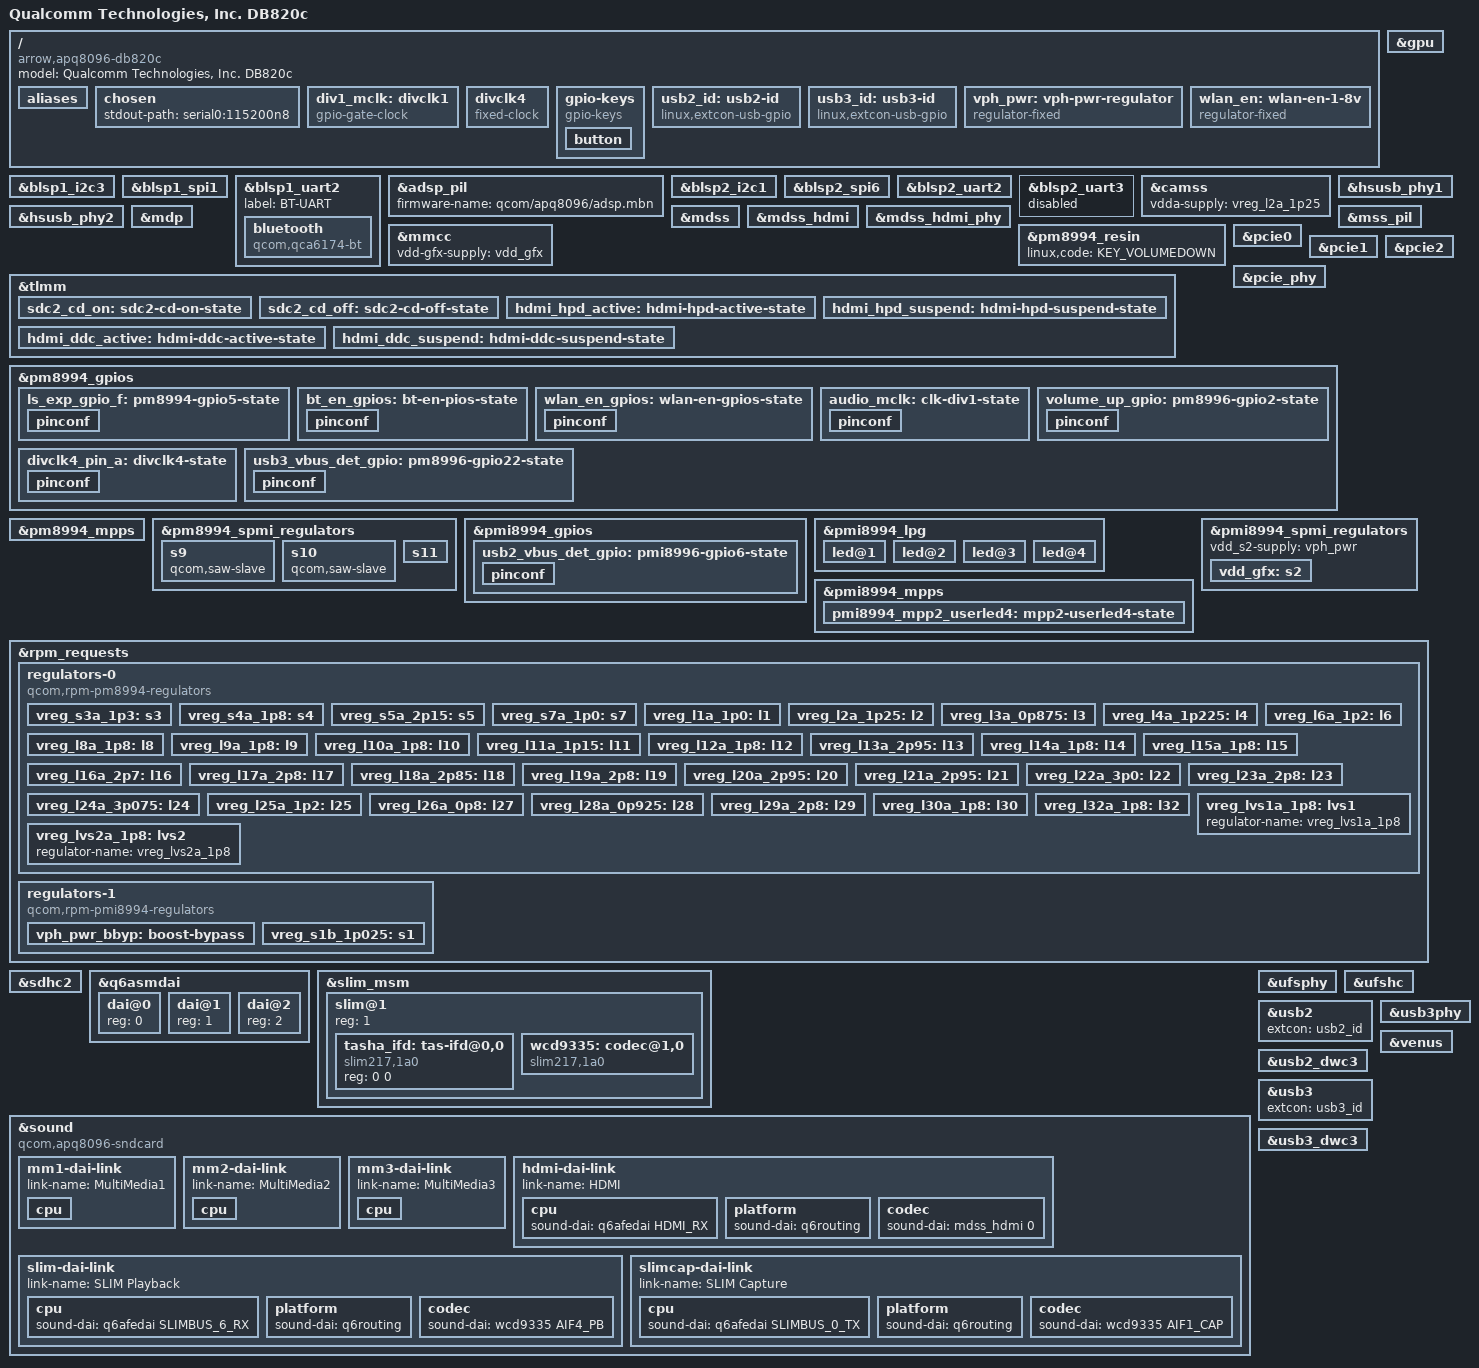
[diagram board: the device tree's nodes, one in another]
/dts-v1/;
#include "msm8996.dtsi"
#include "pm8994.dtsi"
#include "pmi8994.dtsi"
#include <dt-bindings/input/input.h>
#include <dt-bindings/gpio/gpio.h>
#include <dt-bindings/leds/common.h>
#include <dt-bindings/pinctrl/qcom,pmic-gpio.h>
#include <dt-bindings/sound/qcom,q6afe.h>
#include <dt-bindings/sound/qcom,q6asm.h>
#include <dt-bindings/sound/qcom,wcd9335.h>
/ {
	model = "Qualcomm Technologies, Inc. DB820c";
	compatible = "arrow,apq8096-db820c", "qcom,apq8096-sbc", "qcom,apq8096";
	aliases {
		serial0 = &blsp2_uart2;
		serial1 = &blsp2_uart3;
		serial2 = &blsp1_uart2;
		i2c0 = &blsp1_i2c3;
		i2c1 = &blsp2_i2c1;
		i2c2 = &blsp2_i2c1;
		spi0 = &blsp1_spi1;
		spi1 = &blsp2_spi6;
	};
	chosen {
		stdout-path = "serial0:115200n8";
	};
	div1_mclk: divclk1 {
		compatible = "gpio-gate-clock";
		pinctrl-0 = <&audio_mclk>;
		pinctrl-names = "default";
		clocks = <&rpmcc RPM_SMD_DIV_CLK1>;
		#clock-cells = <0>;
		enable-gpios = <&pm8994_gpios 15 0>;
	};
	divclk4: divclk4 {
		compatible = "fixed-clock";
		#clock-cells = <0>;
		clock-frequency = <32768>;
		clock-output-names = "divclk4";
		pinctrl-names = "default";
		pinctrl-0 = <&divclk4_pin_a>;
	};
	gpio-keys {
		compatible = "gpio-keys";
		autorepeat;
		pinctrl-names = "default";
		pinctrl-0 = <&volume_up_gpio>;
		button {
			label = "Volume Up";
			linux,code = <KEY_VOLUMEUP>;
			gpios = <&pm8994_gpios 2 GPIO_ACTIVE_LOW>;
		};
	};
	usb2_id: usb2-id {
		compatible = "linux,extcon-usb-gpio";
		id-gpios = <&pmi8994_gpios 6 GPIO_ACTIVE_HIGH>;
		pinctrl-names = "default";
		pinctrl-0 = <&usb2_vbus_det_gpio>;
	};
	usb3_id: usb3-id {
		compatible = "linux,extcon-usb-gpio";
		id-gpios = <&pm8994_gpios 22 GPIO_ACTIVE_HIGH>;
		pinctrl-names = "default";
		pinctrl-0 = <&usb3_vbus_det_gpio>;
	};
	vph_pwr: vph-pwr-regulator {
		compatible = "regulator-fixed";
		regulator-name = "vph_pwr";
		regulator-always-on;
		regulator-boot-on;
		regulator-min-microvolt = <3700000>;
		regulator-max-microvolt = <3700000>;
	};
	wlan_en: wlan-en-1-8v {
		pinctrl-names = "default";
		pinctrl-0 = <&wlan_en_gpios>;
		compatible = "regulator-fixed";
		regulator-name = "wlan-en-regulator";
		regulator-min-microvolt = <1800000>;
		regulator-max-microvolt = <1800000>;
		gpio = <&pm8994_gpios 8 0>;
		startup-delay-us = <70000>;
		enable-active-high;
	};
};
&blsp1_i2c3 {
	status = "okay";
};
&blsp1_spi1 {
	status = "okay";
};
&blsp1_uart2 {
	label = "BT-UART";
	status = "okay";
	bluetooth {
		compatible = "qcom,qca6174-bt";
		enable-gpios = <&pm8994_gpios 19 GPIO_ACTIVE_HIGH>;
		clocks = <&divclk4>;
	};
};
&adsp_pil {
	status = "okay";
	firmware-name = "qcom/apq8096/adsp.mbn";
};
&blsp2_i2c1 {
	status = "okay";
};
&blsp2_i2c1 {
	status = "okay";
};
&blsp2_spi6 {
	status = "okay";
};
&blsp2_uart2 {
	label = "LS-UART1";
	status = "okay";
	pinctrl-names = "default", "sleep";
	pinctrl-0 = <&blsp2_uart2_2pins_default>;
	pinctrl-1 = <&blsp2_uart2_2pins_sleep>;
};
&blsp2_uart3 {
	label = "LS-UART0";
	status = "disabled";
	pinctrl-names = "default", "sleep";
	pinctrl-0 = <&blsp2_uart3_4pins_default>;
	pinctrl-1 = <&blsp2_uart3_4pins_sleep>;
};
&camss {
	vdda-supply = <&vreg_l2a_1p25>;
};
&gpu {
	status = "okay";
};
&hsusb_phy1 {
	status = "okay";
	vdd-supply = <&vreg_l28a_0p925>;
	vdda-pll-supply = <&vreg_l12a_1p8>;
	vdda-phy-dpdm-supply = <&vreg_l24a_3p075>;
};
&hsusb_phy2 {
	status = "okay";
	vdd-supply = <&vreg_l28a_0p925>;
	vdda-pll-supply = <&vreg_l12a_1p8>;
	vdda-phy-dpdm-supply = <&vreg_l24a_3p075>;
};
&mdp {
	status = "okay";
};
&mdss {
	status = "okay";
};
&mdss_hdmi {
	status = "okay";
	pinctrl-names = "default", "sleep";
	pinctrl-0 = <&hdmi_hpd_active &hdmi_ddc_active>;
	pinctrl-1 = <&hdmi_hpd_suspend &hdmi_ddc_suspend>;
	core-vdda-supply = <&vreg_l12a_1p8>;
	core-vcc-supply = <&vreg_s4a_1p8>;
};
&mdss_hdmi_phy {
	status = "okay";
	vddio-supply = <&vreg_l12a_1p8>;
	vcca-supply = <&vreg_l28a_0p925>;
	#phy-cells = <0>;
};
&mmcc {
	vdd-gfx-supply = <&vdd_gfx>;
};
&mss_pil {
	status = "okay";
	pll-supply = <&vreg_l12a_1p8>;
	firmware-name = "qcom/apq8096/mba.mbn", "qcom/apq8096/modem.mbn";
};
&pm8994_resin {
	status = "okay";
	linux,code = <KEY_VOLUMEDOWN>;
};
&tlmm {
	gpio-line-names =
		"[SPI0_DOUT]",  
		"[SPI0_DIN]",  
		"[SPI0_CS]",  
		"[SPI0_SCLK]",  
		"[UART1_TxD]",  
		"[UART1_RxD]",  
		"[I2C1_SDA]",  
		"[I2C1_SCL]",  
		"GPIO-H",  
		"TP93",  
		"GPIO-G",  
		"[MDP_VSYNC_S]",  
		"NC",  
		"[CSI0_MCLK]",  
		"[CAM_MCLK1]",  
		"[CSI1_MCLK]",  
		"TP99",  
		"[I2C2_SDA]",  
		"[I2C2_SCL]",  
		"[CCI_I2C_SDA1]",  
		"[CCI_I2C_SCL1]",  
		"FLASH_STROBE_EN",  
		"FLASH_STROBE_TRIG",  
		"GPIO-K",  
		"GPIO-D",  
		"GPIO-I",  
		"GPIO-J",  
		"BLSP6_I2C_SDA",  
		"BLSP6_I2C_SCL",  
		"GPIO-B",  
		"GPIO30",  
		"HDMI_CEC",  
		"HDMI_DDC_CLOCK",  
		"HDMI_DDC_DATA",  
		"HDMI_HOT_PLUG_DETECT",  
		"PCIE0_RST_N",  
		"PCIE0_CLKREQ_N",  
		"PCIE0_WAKE",  
		"SD_CARD_DET_N",  
		"TSIF1_SYNC",  
		"W_DISABLE_N",  
		"[BLSP9_UART_TX]",  
		"[BLSP9_UART_RX]",  
		"[BLSP2_UART_CTS_N]",  
		"[BLSP2_UART_RFR_N]",  
		"[BLSP3_UART_TX]",  
		"[BLSP3_UART_RX]",  
		"[I2C0_SDA]",  
		"[I2C0_SCL]",  
		"[UART0_TxD]",  
		"[UART0_RxD]",  
		"[UART0_CTS]",  
		"[UART0_RTS]",  
		"[CODEC_INT1_N]",  
		"[CODEC_INT2_N]",  
		"[BLSP7_I2C_SDA]",  
		"[BLSP7_I2C_SCL]",  
		"MI2S_MCLK",  
		"[PCM_CLK]",  
		"[PCM_FS]",  
		"[PCM_DO]",  
		"[PCM_DI]",  
		"GPIO-E",  
		"TP87",  
		"[CODEC_RST_N]",  
		"[PCM1_CLK]",  
		"[PCM1_SYNC]",  
		"[PCM1_DIN]",  
		"[PCM1_DOUT]",  
		"AUDIO_REF_CLK",  
		"SLIMBUS_CLK",  
		"SLIMBUS_DATA0",  
		"SLIMBUS_DATA1",  
		"NC",  
		"NC",  
		"NC",  
		"NC",  
		"TP94",  
		"NC",  
		"TP95",  
		"GPIO-A",  
		"TP88",  
		"TP89",  
		"TP90",  
		"TP91",  
		"[SD_DAT0]",  
		"[SD_CMD]",  
		"[SD_DAT3]",  
		"[SD_SCLK]",  
		"TSIF1_CLK",  
		"TSIF1_EN",  
		"TSIF1_DATA",  
		"NC",  
		"TSIF2_CLK",  
		"TSIF2_EN",  
		"TSIF2_DATA",  
		"TSIF2_SYNC",  
		"NC",  
		"CAM1_STANDBY_N",  
		"NC",  
		"NC",  
		"[LCD1_RESET_N]",  
		"BOOT_CONFIG1",  
		"USB_HUB_RESET",  
		"CAM1_RST_N",  
		"NC",  
		"NC",  
		"NC",  
		"NC",  
		"NC",  
		"NC",  
		"NC",  
		"NC",  
		"PMI8994_BUA",  
		"PCIE2_RST_N",  
		"PCIE2_CLKREQ_N",  
		"PCIE2_WAKE",  
		"SSC_IRQ_0",  
		"SSC_IRQ_1",  
		"SSC_IRQ_2",  
		"NC",  
		"GPIO121",  
		"NC",  
		"SSC_IRQ_6",  
		"SSC_IRQ_7",  
		"GPIO-C",  
		"BOOT_CONFIG5",  
		"NC",  
		"NC",  
		"BOOT_CONFIG7",  
		"PCIE1_RST_N",  
		"PCIE1_CLKREQ_N",  
		"PCIE1_WAKE",  
		"GPIO-L",  
		"NC",  
		"NC",  
		"BOOT_CONFIG8",  
		"NC",  
		"NC",  
		"GPS_SSBI2",  
		"GPS_SSBI1",  
		"NC",  
		"NC",  
		"NC",  
		"BOOT_CONFIG6",  
		"NC",  
		"NC",  
		"NC",  
		"NC",  
		"NC";  
	sdc2_cd_on: sdc2-cd-on-state {
		pins = "gpio38";
		function = "gpio";
		bias-pull-up;
		drive-strength = <16>;
	};
	sdc2_cd_off: sdc2-cd-off-state {
		pins = "gpio38";
		function = "gpio";
		bias-pull-up;
		drive-strength = <2>;
	};
	hdmi_hpd_active: hdmi-hpd-active-state {
		pins = "gpio34";
		function = "hdmi_hot";
		bias-pull-down;
		drive-strength = <16>;
	};
	hdmi_hpd_suspend: hdmi-hpd-suspend-state {
		pins = "gpio34";
		function = "hdmi_hot";
		bias-pull-down;
		drive-strength = <2>;
	};
	hdmi_ddc_active: hdmi-ddc-active-state {
		pins = "gpio32", "gpio33";
		function = "hdmi_ddc";
		drive-strength = <2>;
		bias-pull-up;
	};
	hdmi_ddc_suspend: hdmi-ddc-suspend-state {
		pins = "gpio32", "gpio33";
		function = "hdmi_ddc";
		drive-strength = <2>;
		bias-pull-down;
	};
};
&pcie0 {
	status = "okay";
	perst-gpios = <&tlmm 35 GPIO_ACTIVE_LOW>;
	vddpe-3v3-supply = <&wlan_en>;
	vdda-supply = <&vreg_l28a_0p925>;
};
&pcie1 {
	status = "okay";
	perst-gpios = <&tlmm 130 GPIO_ACTIVE_LOW>;
	vdda-supply = <&vreg_l28a_0p925>;
};
&pcie2 {
	status = "okay";
	perst-gpios = <&tlmm 114 GPIO_ACTIVE_LOW>;
	vdda-supply = <&vreg_l28a_0p925>;
};
&pcie_phy {
	status = "okay";
	vdda-phy-supply = <&vreg_l28a_0p925>;
	vdda-pll-supply = <&vreg_l12a_1p8>;
};
&pm8994_gpios {
	gpio-line-names =
		"NC",
		"KEY_VOLP_N",
		"NC",
		"BL1_PWM",
		"GPIO-F",  
		"BL1_EN",
		"NC",
		"WLAN_EN",
		"NC",
		"NC",
		"NC",
		"NC",
		"NC",
		"NC",
		"DIVCLK1",
		"DIVCLK2",
		"DIVCLK3",
		"DIVCLK4",
		"BT_EN",
		"PMIC_SLB",
		"PMIC_BUA",
		"USB_VBUS_DET";
	pinctrl-names = "default";
	pinctrl-0 = <&ls_exp_gpio_f &bt_en_gpios>;
	ls_exp_gpio_f: pm8994-gpio5-state {
		pinconf {
			pins = "gpio5";
			function = PMIC_GPIO_FUNC_NORMAL;
			output-low;
			power-source = <PM8994_GPIO_S4>;  
		};
	};
	bt_en_gpios: bt-en-pios-state {
		pinconf {
			pins = "gpio19";
			function = PMIC_GPIO_FUNC_NORMAL;
			output-low;
			power-source = <PM8994_GPIO_S4>;  
			qcom,drive-strength = <PMIC_GPIO_STRENGTH_LOW>;
			bias-pull-down;
		};
	};
	wlan_en_gpios: wlan-en-gpios-state {
		pinconf {
			pins = "gpio8";
			function = PMIC_GPIO_FUNC_NORMAL;
			output-low;
			power-source = <PM8994_GPIO_S4>;  
			qcom,drive-strength = <PMIC_GPIO_STRENGTH_LOW>;
			bias-pull-down;
		};
	};
	audio_mclk: clk-div1-state {
		pinconf {
			pins = "gpio15";
			function = "func1";
			power-source = <PM8994_GPIO_S4>;  
		};
	};
	volume_up_gpio: pm8996-gpio2-state {
		pinconf {
			pins = "gpio2";
			function = "normal";
			input-enable;
			drive-push-pull;
			bias-pull-up;
			qcom,drive-strength = <PMIC_GPIO_STRENGTH_NO>;
			power-source = <PM8994_GPIO_S4>;  
		};
	};
	divclk4_pin_a: divclk4-state {
		pinconf {
			pins = "gpio18";
			function = PMIC_GPIO_FUNC_FUNC2;
			bias-disable;
			power-source = <PM8994_GPIO_S4>;
		};
	};
	usb3_vbus_det_gpio: pm8996-gpio22-state {
		pinconf {
			pins = "gpio22";
			function = PMIC_GPIO_FUNC_NORMAL;
			input-enable;
			bias-pull-down;
			qcom,drive-strength = <PMIC_GPIO_STRENGTH_NO>;
			power-source = <PM8994_GPIO_S4>;  
		};
	};
};
&pm8994_mpps {
	gpio-line-names =
		"VDDPX_BIAS",
		"WIFI_LED",
		"NC",
		"BT_LED",
		"PM_MPP05",
		"PM_MPP06",
		"PM_MPP07",
		"NC";
};
&pm8994_spmi_regulators {
	qcom,saw-reg = <&saw3>;
	vdd_s11-supply = <&vph_pwr>;
	s9 {
		qcom,saw-slave;
	};
	s10 {
		qcom,saw-slave;
	};
	s11 {
		qcom,saw-leader;
		regulator-name = "VDD_APCC";
		regulator-always-on;
		regulator-min-microvolt = <980000>;
		regulator-max-microvolt = <980000>;
	};
};
&pmi8994_gpios {
	gpio-line-names =
		"NC",
		"SPKR_AMP_EN1",
		"SPKR_AMP_EN2",
		"TP61",
		"NC",
		"USB2_VBUS_DET",
		"NC",
		"NC",
		"NC",
		"NC";
	usb2_vbus_det_gpio: pmi8996-gpio6-state {
		pinconf {
			pins = "gpio6";
			function = PMIC_GPIO_FUNC_NORMAL;
			input-enable;
			bias-pull-down;
			qcom,drive-strength = <PMIC_GPIO_STRENGTH_NO>;
			power-source = <PM8994_GPIO_S4>;  
		};
	};
};
&pmi8994_lpg {
	qcom,power-source = <1>;
	pinctrl-names = "default";
	pinctrl-0 = <&pmi8994_mpp2_userled4>;
	qcom,dtest = <0 0>,
		     <0 0>,
		     <0 0>,
		     <4 1>;
	status = "okay";
	led@1 {
		reg = <1>;
		color = <LED_COLOR_ID_GREEN>;
		function = LED_FUNCTION_HEARTBEAT;
		function-enumerator = <1>;
		linux,default-trigger = "heartbeat";
		default-state = "on";
	};
	led@2 {
		reg = <2>;
		color = <LED_COLOR_ID_GREEN>;
		function = LED_FUNCTION_HEARTBEAT;
		function-enumerator = <0>;
	};
	led@3 {
		reg = <3>;
		color = <LED_COLOR_ID_GREEN>;
		function = LED_FUNCTION_HEARTBEAT;
		function-enumerator = <2>;
	};
	led@4 {
		reg = <4>;
		color = <LED_COLOR_ID_GREEN>;
		function = LED_FUNCTION_HEARTBEAT;
		function-enumerator = <3>;
	};
};
&pmi8994_mpps {
	pmi8994_mpp2_userled4: mpp2-userled4-state {
		pins = "mpp2";
		function = "sink";
		output-low;
		qcom,dtest = <4>;
	};
};
&pmi8994_spmi_regulators {
	vdd_s2-supply = <&vph_pwr>;
	vdd_gfx: s2 {
		regulator-name = "VDD_GFX";
		regulator-min-microvolt = <980000>;
		regulator-max-microvolt = <980000>;
	};
};
&rpm_requests {
	regulators-0 {
		compatible = "qcom,rpm-pm8994-regulators";
		vdd_s1-supply = <&vph_pwr>;
		vdd_s2-supply = <&vph_pwr>;
		vdd_s3-supply = <&vph_pwr>;
		vdd_s4-supply = <&vph_pwr>;
		vdd_s5-supply = <&vph_pwr>;
		vdd_s6-supply = <&vph_pwr>;
		vdd_s7-supply = <&vph_pwr>;
		vdd_s8-supply = <&vph_pwr>;
		vdd_s9-supply = <&vph_pwr>;
		vdd_s10-supply = <&vph_pwr>;
		vdd_s11-supply = <&vph_pwr>;
		vdd_s12-supply = <&vph_pwr>;
		vdd_l1-supply = <&vreg_s1b_1p025>;
		vdd_l2_l26_l28-supply = <&vreg_s3a_1p3>;
		vdd_l3_l11-supply = <&vreg_s3a_1p3>;
		vdd_l4_l27_l31-supply = <&vreg_s3a_1p3>;
		vdd_l5_l7-supply = <&vreg_s5a_2p15>;
		vdd_l6_l12_l32-supply = <&vreg_s5a_2p15>;
		vdd_l8_l16_l30-supply = <&vph_pwr>;
		vdd_l9_l10_l18_l22-supply = <&vph_pwr_bbyp>;
		vdd_l13_l19_l23_l24-supply = <&vph_pwr_bbyp>;
		vdd_l14_l15-supply = <&vreg_s5a_2p15>;
		vdd_l17_l29-supply = <&vph_pwr_bbyp>;
		vdd_l20_l21-supply = <&vph_pwr_bbyp>;
		vdd_l25-supply = <&vreg_s3a_1p3>;
		vdd_lvs1_2-supply = <&vreg_s4a_1p8>;
		vreg_s3a_1p3: s3 {
			regulator-name = "vreg_s3a_1p3";
			regulator-min-microvolt = <1300000>;
			regulator-max-microvolt = <1300000>;
		};
		vreg_s4a_1p8: s4 {
			regulator-name = "vreg_s4a_1p8";
			regulator-min-microvolt = <1800000>;
			regulator-max-microvolt = <1800000>;
			regulator-always-on;
		};
		vreg_s5a_2p15: s5 {
			regulator-name = "vreg_s5a_2p15";
			regulator-min-microvolt = <2150000>;
			regulator-max-microvolt = <2150000>;
		};
		vreg_s7a_1p0: s7 {
			regulator-name = "vreg_s7a_1p0";
			regulator-min-microvolt = <800000>;
			regulator-max-microvolt = <800000>;
		};
		vreg_l1a_1p0: l1 {
			regulator-name = "vreg_l1a_1p0";
			regulator-min-microvolt = <1000000>;
			regulator-max-microvolt = <1000000>;
		};
		vreg_l2a_1p25: l2 {
			regulator-name = "vreg_l2a_1p25";
			regulator-min-microvolt = <1250000>;
			regulator-max-microvolt = <1250000>;
		};
		vreg_l3a_0p875: l3 {
			regulator-name = "vreg_l3a_0p875";
			regulator-min-microvolt = <850000>;
			regulator-max-microvolt = <850000>;
		};
		vreg_l4a_1p225: l4 {
			regulator-name = "vreg_l4a_1p225";
			regulator-min-microvolt = <1225000>;
			regulator-max-microvolt = <1225000>;
		};
		vreg_l6a_1p2: l6 {
			regulator-name = "vreg_l6a_1p2";
			regulator-min-microvolt = <1200000>;
			regulator-max-microvolt = <1200000>;
		};
		vreg_l8a_1p8: l8 {
			regulator-name = "vreg_l8a_1p8";
			regulator-min-microvolt = <1800000>;
			regulator-max-microvolt = <1800000>;
		};
		vreg_l9a_1p8: l9 {
			regulator-name = "vreg_l9a_1p8";
			regulator-min-microvolt = <1800000>;
			regulator-max-microvolt = <1800000>;
		};
		vreg_l10a_1p8: l10 {
			regulator-name = "vreg_l10a_1p8";
			regulator-min-microvolt = <1800000>;
			regulator-max-microvolt = <1800000>;
		};
		vreg_l11a_1p15: l11 {
			regulator-name = "vreg_l11a_1p15";
			regulator-min-microvolt = <1150000>;
			regulator-max-microvolt = <1150000>;
		};
		vreg_l12a_1p8: l12 {
			regulator-name = "vreg_l12a_1p8";
			regulator-min-microvolt = <1800000>;
			regulator-max-microvolt = <1800000>;
		};
		vreg_l13a_2p95: l13 {
			regulator-name = "vreg_l13a_2p95";
			regulator-min-microvolt = <1800000>;
			regulator-max-microvolt = <2950000>;
		};
		vreg_l14a_1p8: l14 {
			regulator-name = "vreg_l14a_1p8";
			regulator-min-microvolt = <1800000>;
			regulator-max-microvolt = <1800000>;
		};
		vreg_l15a_1p8: l15 {
			regulator-name = "vreg_l15a_1p8";
			regulator-min-microvolt = <1800000>;
			regulator-max-microvolt = <1800000>;
		};
		vreg_l16a_2p7: l16 {
			regulator-name = "vreg_l16a_2p7";
			regulator-min-microvolt = <2700000>;
			regulator-max-microvolt = <2700000>;
		};
		vreg_l17a_2p8: l17 {
			regulator-name = "vreg_l17a_2p8";
			regulator-min-microvolt = <2500000>;
			regulator-max-microvolt = <2500000>;
		};
		vreg_l18a_2p85: l18 {
			regulator-name = "vreg_l18a_2p85";
			regulator-min-microvolt = <2700000>;
			regulator-max-microvolt = <2900000>;
		};
		vreg_l19a_2p8: l19 {
			regulator-name = "vreg_l19a_2p8";
			regulator-min-microvolt = <3000000>;
			regulator-max-microvolt = <3000000>;
		};
		vreg_l20a_2p95: l20 {
			regulator-name = "vreg_l20a_2p95";
			regulator-min-microvolt = <2950000>;
			regulator-max-microvolt = <2950000>;
			regulator-allow-set-load;
		};
		vreg_l21a_2p95: l21 {
			regulator-name = "vreg_l21a_2p95";
			regulator-min-microvolt = <2950000>;
			regulator-max-microvolt = <2950000>;
			regulator-allow-set-load;
			regulator-system-load = <200000>;
		};
		vreg_l22a_3p0: l22 {
			regulator-name = "vreg_l22a_3p0";
			regulator-min-microvolt = <3300000>;
			regulator-max-microvolt = <3300000>;
		};
		vreg_l23a_2p8: l23 {
			regulator-name = "vreg_l23a_2p8";
			regulator-min-microvolt = <2800000>;
			regulator-max-microvolt = <2800000>;
		};
		vreg_l24a_3p075: l24 {
			regulator-name = "vreg_l24a_3p075";
			regulator-min-microvolt = <3075000>;
			regulator-max-microvolt = <3075000>;
		};
		vreg_l25a_1p2: l25 {
			regulator-name = "vreg_l25a_1p2";
			regulator-min-microvolt = <1200000>;
			regulator-max-microvolt = <1200000>;
			regulator-allow-set-load;
		};
		vreg_l26a_0p8: l27 {
			regulator-name = "vreg_l26a_0p8";
			regulator-min-microvolt = <1000000>;
			regulator-max-microvolt = <1000000>;
		};
		vreg_l28a_0p925: l28 {
			regulator-name = "vreg_l28a_0p925";
			regulator-min-microvolt = <925000>;
			regulator-max-microvolt = <925000>;
			regulator-allow-set-load;
		};
		vreg_l29a_2p8: l29 {
			regulator-name = "vreg_l29a_2p8";
			regulator-min-microvolt = <2800000>;
			regulator-max-microvolt = <2800000>;
		};
		vreg_l30a_1p8: l30 {
			regulator-name = "vreg_l30a_1p8";
			regulator-min-microvolt = <1800000>;
			regulator-max-microvolt = <1800000>;
		};
		vreg_l32a_1p8: l32 {
			regulator-name = "vreg_l32a_1p8";
			regulator-min-microvolt = <1800000>;
			regulator-max-microvolt = <1800000>;
		};
		vreg_lvs1a_1p8: lvs1 {
			regulator-name = "vreg_lvs1a_1p8";
		};
		vreg_lvs2a_1p8: lvs2 {
			regulator-name = "vreg_lvs2a_1p8";
		};
	};
	regulators-1 {
		compatible = "qcom,rpm-pmi8994-regulators";
		vdd_s1-supply = <&vph_pwr>;
		vdd_s2-supply = <&vph_pwr>;
		vdd_s3-supply = <&vph_pwr>;
		vdd_bst_byp-supply = <&vph_pwr>;
		vph_pwr_bbyp: boost-bypass {
			regulator-name = "vph_pwr_bbyp";
			regulator-min-microvolt = <3300000>;
			regulator-max-microvolt = <3300000>;
		};
		vreg_s1b_1p025: s1 {
			regulator-name = "vreg_s1b_1p025";
			regulator-min-microvolt = <1025000>;
			regulator-max-microvolt = <1025000>;
		};
	};
};
&sdhc2 {
	pinctrl-names = "default", "sleep";
	pinctrl-0 = <&sdc2_state_on &sdc2_cd_on>;
	pinctrl-1 = <&sdc2_state_off &sdc2_cd_off>;
	cd-gpios = <&tlmm 38 GPIO_ACTIVE_LOW>;
	vmmc-supply = <&vreg_l21a_2p95>;
	vqmmc-supply = <&vreg_l13a_2p95>;
	status = "okay";
};
&q6asmdai {
	dai@0 {
		reg = <0>;
	};
	dai@1 {
		reg = <1>;
	};
	dai@2 {
		reg = <2>;
	};
};
&slim_msm {
	status = "okay";
	slim@1 {
		reg = <1>;
		#address-cells = <2>;
		#size-cells = <0>;
		tasha_ifd: tas-ifd@0,0 {
			compatible = "slim217,1a0";
			reg = <0 0>;
		};
		wcd9335: codec@1,0 {
			compatible = "slim217,1a0";
			reg = <1 0>;
			clock-names = "mclk", "slimbus";
			clocks = <&div1_mclk>,
				 <&rpmcc RPM_SMD_BB_CLK1>;
			interrupt-parent = <&tlmm>;
			interrupts = <54 IRQ_TYPE_LEVEL_HIGH>,
				     <53 IRQ_TYPE_LEVEL_HIGH>;
			interrupt-names = "intr1", "intr2";
			interrupt-controller;
			#interrupt-cells = <1>;
			pinctrl-0 = <&cdc_reset_active &wcd_intr_default>;
			pinctrl-names = "default";
			reset-gpios = <&tlmm 64 GPIO_ACTIVE_LOW>;
			slim-ifc-dev = <&tasha_ifd>;
			#sound-dai-cells = <1>;
			vdd-buck-supply = <&vreg_s4a_1p8>;
			vdd-buck-sido-supply = <&vreg_s4a_1p8>;
			vdd-tx-supply = <&vreg_s4a_1p8>;
			vdd-rx-supply = <&vreg_s4a_1p8>;
			vdd-io-supply = <&vreg_s4a_1p8>;
		};
	};
};
&sound {
	compatible = "qcom,apq8096-sndcard";
	model = "DB820c";
	audio-routing = "RX_BIAS", "MCLK",
		"MM_DL1",  "MultiMedia1 Playback",
		"MM_DL2",  "MultiMedia2 Playback",
		"MultiMedia3 Capture", "MM_UL3";
	mm1-dai-link {
		link-name = "MultiMedia1";
		cpu {
			sound-dai = <&q6asmdai  MSM_FRONTEND_DAI_MULTIMEDIA1>;
		};
	};
	mm2-dai-link {
		link-name = "MultiMedia2";
		cpu {
			sound-dai = <&q6asmdai  MSM_FRONTEND_DAI_MULTIMEDIA2>;
		};
	};
	mm3-dai-link {
		link-name = "MultiMedia3";
		cpu {
			sound-dai = <&q6asmdai  MSM_FRONTEND_DAI_MULTIMEDIA3>;
		};
	};
	hdmi-dai-link {
		link-name = "HDMI";
		cpu {
			sound-dai = <&q6afedai HDMI_RX>;
		};
		platform {
			sound-dai = <&q6routing>;
		};
		codec {
			sound-dai = <&mdss_hdmi 0>;
		};
	};
	slim-dai-link {
		link-name = "SLIM Playback";
		cpu {
			sound-dai = <&q6afedai SLIMBUS_6_RX>;
		};
		platform {
			sound-dai = <&q6routing>;
		};
		codec {
			sound-dai = <&wcd9335 AIF4_PB>;
		};
	};
	slimcap-dai-link {
		link-name = "SLIM Capture";
		cpu {
			sound-dai = <&q6afedai SLIMBUS_0_TX>;
		};
		platform {
			sound-dai = <&q6routing>;
		};
		codec {
			sound-dai = <&wcd9335 AIF1_CAP>;
		};
	};
};
&ufsphy {
	status = "okay";
	vdda-phy-supply = <&vreg_l28a_0p925>;
	vdda-pll-supply = <&vreg_l12a_1p8>;
	vddp-ref-clk-supply = <&vreg_l25a_1p2>;
};
&ufshc {
	status = "okay";
	vcc-supply = <&vreg_l20a_2p95>;
	vccq-supply = <&vreg_l25a_1p2>;
	vccq2-supply = <&vreg_s4a_1p8>;
	vcc-max-microamp = <600000>;
	vccq-max-microamp = <450000>;
	vccq2-max-microamp = <450000>;
};
&usb2 {
	status = "okay";
	extcon = <&usb2_id>;
};
&usb2_dwc3 {
	extcon = <&usb2_id>;
	dr_mode = "otg";
	maximum-speed = "high-speed";
};
&usb3 {
	status = "okay";
	extcon = <&usb3_id>;
};
&usb3_dwc3 {
	extcon = <&usb3_id>;
	dr_mode = "otg";
};
&usb3phy {
	status = "okay";
	vdda-phy-supply = <&vreg_l28a_0p925>;
	vdda-pll-supply = <&vreg_l12a_1p8>;
};
&venus {
	status = "okay";
};
